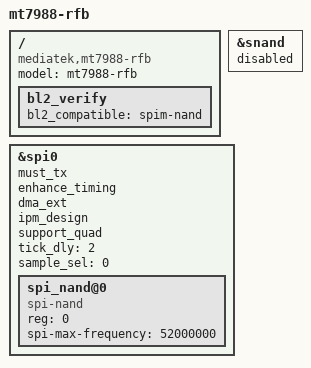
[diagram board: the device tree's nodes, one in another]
// SPDX-License-Identifier: GPL-2.0
/*
 * Copyright (c) 2022 MediaTek Inc.
 * Author: Sam Shih <sam.shih@mediatek.com>
 */

/dts-v1/;
#include "mt7988-gmac2-rfb.dts"
#include <dt-bindings/gpio/gpio.h>

/ {
	model = "mt7988-rfb";
	compatible = "mediatek,mt7988-rfb", "mediatek,mt7988-spim-nand-rfb";

	bl2_verify {
		bl2_compatible = "spim-nand";
	};
};

&snand {
	status = "disabled";
};

&spi0 {
	#address-cells = <1>;
	#size-cells = <0>;
	status = "okay";
	must_tx;
	enhance_timing;
	dma_ext;
	ipm_design;
	support_quad;
	tick_dly = <2>;
	sample_sel = <0>;

	spi_nand@0 {
		compatible = "spi-nand";
		reg = <0>;
		spi-max-frequency = <52000000>;
	};
};
